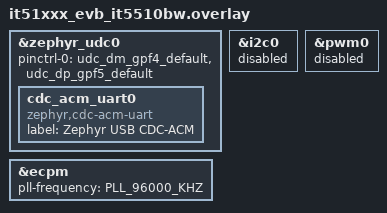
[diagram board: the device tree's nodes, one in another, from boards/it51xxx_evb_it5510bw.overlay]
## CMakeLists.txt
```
# SPDX-License-Identifier: Apache-2.0

cmake_minimum_required(VERSION 3.20.0)
find_package(Zephyr REQUIRED HINTS $ENV{ZEPHYR_BASE})
project(cdc_acm)

set(SAMPLE_USBD_DIR ${ZEPHYR_BASE}/samples/subsys/usb/common)
FILE(GLOB app_sources src/*.c)

target_include_directories(app PRIVATE ${SAMPLE_USBD_DIR})

target_sources(app PRIVATE ${app_sources})

target_sources_ifdef(CONFIG_USB_DEVICE_STACK_NEXT app PRIVATE
	${SAMPLE_USBD_DIR}/sample_usbd_init.c
)
```

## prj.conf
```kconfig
#CONFIG_STDOUT_CONSOLE=y
#CONFIG_USB_DEVICE_STACK=y
#CONFIG_USB_DEVICE_PRODUCT="Zephyr CDC ACM sample"
#CONFIG_USB_DEVICE_PID=0x0001
#CONFIG_LOG=y
#CONFIG_USB_DRIVER_LOG_LEVEL_ERR=y
#CONFIG_USB_DEVICE_LOG_LEVEL_ERR=y
#CONFIG_SERIAL=y
CONFIG_UART_INTERRUPT_DRIVEN=y
#CONFIG_UART_LINE_CTRL=y
#CONFIG_USB_DEVICE_INITIALIZE_AT_BOOT=n

CONFIG_SHELL=y
CONFIG_SHELL_LOG_LEVEL_INF=y

CONFIG_USB_DEVICE_STACK_NEXT=y
CONFIG_STDOUT_CONSOLE=y
CONFIG_SERIAL=y
CONFIG_UART_LINE_CTRL=y
CONFIG_USBD_CDC_ACM_CLASS=y
CONFIG_LOG=y
CONFIG_USBD_LOG_LEVEL_WRN=y
CONFIG_UDC_DRIVER_LOG_LEVEL_WRN=y

CONFIG_USBD_SHELL=y
```

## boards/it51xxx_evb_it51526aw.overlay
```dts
/*
 * Copyright (c) 2026 ITE Corporation. All Rights Reserved.
 *
 * SPDX-License-Identifier: Apache-2.0
 */

&zephyr_udc0 {
	status = "okay";
	pinctrl-0 = <&udc_dm_gpf4_default &udc_dp_gpf5_default>;
	pinctrl-names = "default";
	cdc_acm_uart0 {
		compatible = "zephyr,cdc-acm-uart";
		label = "Zephyr USB CDC-ACM";
	};
};

&ecpm {
	pll-frequency = <PLL_96000_KHZ>;
};
```

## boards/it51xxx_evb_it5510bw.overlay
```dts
/*
 * Copyright (c) 2026 ITE Corporation. All Rights Reserved.
 *
 * SPDX-License-Identifier: Apache-2.0
 */

&zephyr_udc0 {
	status = "okay";

	/* it5510.bw udc controller selects gpiof2/gpiof3 */
	// extend-ctrl = <0xf016cf 0 1>;
	// pinctrl-0 = <&uhc_ym_gpf2_default &uhc_yp_gpf3_default>;

	/* it5510.bw udc controller selects gpiof4/gpiof5 */
	pinctrl-0 = <&udc_dm_gpf4_default &udc_dp_gpf5_default>;
	pinctrl-names = "default";
	cdc_acm_uart0 {
		compatible = "zephyr,cdc-acm-uart";
		label = "Zephyr USB CDC-ACM";
	};
};

&ecpm {
	pll-frequency = <PLL_96000_KHZ>;
};

/* disable i2c0(gpiof2/gpiof3) if it5510.bw udc controller selects gpiof2/gpiof3 */
&i2c0 {
	status = "disabled";
};

&pwm0 {
	status = "disabled";
};
```

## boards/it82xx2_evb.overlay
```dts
&zephyr_udc0 {
	status = "okay";

	cdc_acm_uart0 {
		compatible = "zephyr,cdc-acm-uart";
		label = "Zephyr USB CDC-ACM";
	};
};

&pwm0 {
	status = "disabled";
};
```

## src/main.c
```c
/*
 * Copyright (c) 2019 Intel Corporation
 *
 * SPDX-License-Identifier: Apache-2.0
 */

#include <sample_usbd.h>

#include <stdio.h>
#include <string.h>
#include <zephyr/device.h>
#include <zephyr/drivers/uart.h>
#include <zephyr/kernel.h>
#include <zephyr/sys/ring_buffer.h>

#include <zephyr/usb/usbd.h>
#include <zephyr/logging/log.h>
LOG_MODULE_REGISTER(cdc_acm_echo, LOG_LEVEL_INF);

const struct device *const uart_dev = DEVICE_DT_GET_ONE(zephyr_cdc_acm_uart);

#define RING_BUF_SIZE 1024
uint8_t ring_buffer[RING_BUF_SIZE];

struct ring_buf ringbuf;

static bool rx_throttled;

static inline void print_baudrate(const struct device *dev)
{
	uint32_t baudrate;
	int ret;

	ret = uart_line_ctrl_get(dev, UART_LINE_CTRL_BAUD_RATE, &baudrate);
	if (ret) {
		LOG_WRN("Failed to get baudrate, ret code %d", ret);
	} else {
		LOG_INF("Baudrate %u", baudrate);
		if (baudrate == 115200) {
			k_msleep(3000);
#if CONFIG_SOC_IT51XXX
			sys_write8(0x44, 0xf01610);
#endif
#if CONFIG_SOC_IT8XXX2
			sys_write8(0x44, 0xf01660);
#endif
			sys_write8(sys_read8(0xf01601) | BIT(0), 0xf01601);
			k_msleep(10);
			sys_write8(sys_read8(0xf01601) & ~BIT(0), 0xf01601);
			k_msleep(10);
		}
	}
}

static struct usbd_context *sample_usbd;
K_SEM_DEFINE(dtr_sem, 0, 1);

static void sample_msg_cb(struct usbd_context *const ctx, const struct usbd_msg *msg)
{
	LOG_INF("USBD message: %s", usbd_msg_type_string(msg->type));

	if (usbd_can_detect_vbus(ctx)) {
		if (msg->type == USBD_MSG_VBUS_READY) {
			if (usbd_enable(ctx)) {
				LOG_ERR("Failed to enable device support");
			}
		}

		if (msg->type == USBD_MSG_VBUS_REMOVED) {
			if (usbd_disable(ctx)) {
				LOG_ERR("Failed to disable device support");
			}
		}
	}

	if (msg->type == USBD_MSG_CDC_ACM_CONTROL_LINE_STATE) {
		uint32_t dtr = 0U;

		uart_line_ctrl_get(msg->dev, UART_LINE_CTRL_DTR, &dtr);
		if (dtr) {
			k_sem_give(&dtr_sem);
		}
	}

	if (msg->type == USBD_MSG_CDC_ACM_LINE_CODING) {
		print_baudrate(msg->dev);
	}
}

static int enable_usb_device_next(void)
{
	int err;

	sample_usbd = sample_usbd_init_device(sample_msg_cb);
	if (sample_usbd == NULL) {
		LOG_ERR("Failed to initialize USB device");
		return -ENODEV;
	}

	if (!usbd_can_detect_vbus(sample_usbd)) {
		err = usbd_enable(sample_usbd);
		if (err) {
			LOG_ERR("Failed to enable device support");
			return err;
		}
	}

	LOG_INF("USB device support enabled");

	return 0;
}

static void interrupt_handler(const struct device *dev, void *user_data)
{
	ARG_UNUSED(user_data);

	while (true) {
		uart_irq_update(dev);

		if (uart_irq_is_pending(dev) <= 0) {
			break;
		}

		if (!rx_throttled && uart_irq_rx_ready(dev)) {
			int recv_len, rb_len;
			uint8_t buffer[64];
			size_t len = MIN(ring_buf_space_get(&ringbuf),
					 sizeof(buffer));

			if (len == 0) {
				/* Throttle because ring buffer is full */
				uart_irq_rx_disable(dev);
				rx_throttled = true;
				continue;
			}

			recv_len = uart_fifo_read(dev, buffer, len);
			if (recv_len < 0) {
				LOG_ERR("Failed to read UART FIFO");
				recv_len = 0;
			};

			rb_len = ring_buf_put(&ringbuf, buffer, recv_len);
			if (rb_len < recv_len) {
				LOG_ERR("Drop %u bytes", recv_len - rb_len);
			}

			LOG_DBG("tty fifo -> ringbuf %d bytes", rb_len);
			if (rb_len) {
				uart_irq_tx_enable(dev);
			}
		}

		if (uart_irq_tx_ready(dev)) {
			uint8_t buffer[64];
			int rb_len, send_len;

			rb_len = ring_buf_get(&ringbuf, buffer, sizeof(buffer));
			if (!rb_len) {
				LOG_DBG("Ring buffer empty, disable TX IRQ");
				uart_irq_tx_disable(dev);
				continue;
			}

			if (rx_throttled) {
				uart_irq_rx_enable(dev);
				rx_throttled = false;
			}

			send_len = uart_fifo_fill(dev, buffer, rb_len);
			if (send_len < rb_len) {
				LOG_ERR("Drop %d bytes", rb_len - send_len);
			}

			LOG_DBG("ringbuf -> tty fifo %d bytes", send_len);
		}
	}
}

int main(void)
{
	int ret;

	if (!device_is_ready(uart_dev)) {
		LOG_ERR("CDC ACM device not ready");
		return 0;
	}

	ret = enable_usb_device_next();
	if (ret != 0) {
		LOG_ERR("Failed to enable USB device support");
		return 0;
	}

	ring_buf_init(&ringbuf, sizeof(ring_buffer), ring_buffer);

	LOG_INF("Wait for DTR");
	k_sem_take(&dtr_sem, K_FOREVER);
	LOG_INF("DTR set");

	/* They are optional, we use them to test the interrupt endpoint */
	ret = uart_line_ctrl_set(uart_dev, UART_LINE_CTRL_DCD, 1);
	if (ret) {
		LOG_WRN("Failed to set DCD, ret code %d", ret);
	}

	ret = uart_line_ctrl_set(uart_dev, UART_LINE_CTRL_DSR, 1);
	if (ret) {
		LOG_WRN("Failed to set DSR, ret code %d", ret);
	}

	/* Wait 100ms for the host to do all settings */
	k_msleep(100);

	uart_irq_callback_set(uart_dev, interrupt_handler);
	/* Enable rx interrupts */
	uart_irq_rx_enable(uart_dev);

	return 0;
}
```
